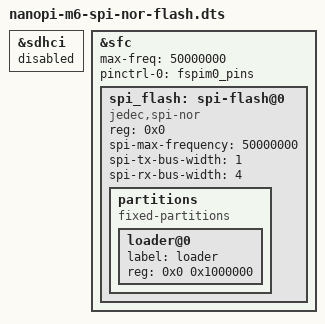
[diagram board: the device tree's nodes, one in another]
/dts-v1/;
/plugin/;

/ {
	fragment@0 {
		target = <&sdhci>;

		__overlay__ {
			status = "disabled";
		};
	};

	fragment@1 {
		target = <&sfc>;

		__overlay__ {
			max-freq = <50000000>;
			#address-cells = <1>;
			#size-cells = <0>;
			pinctrl-names = "default";
			pinctrl-0 = <&fspim0_pins>;
			status = "okay";

			spi_flash: spi-flash@0 {
				#address-cells = <1>;
				#size-cells = <0>;
				compatible = "jedec,spi-nor";
				reg = <0x0>;
				spi-max-frequency = <50000000>;
				spi-tx-bus-width = <1>;
				spi-rx-bus-width = <4>;
				status = "okay";

				partitions {
					compatible = "fixed-partitions";
					#address-cells = <1>;
					#size-cells = <1>;

					loader@0 {
						label = "loader";
						reg = <0x0 0x1000000>;
					};
				};
			};
		};
	};
};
